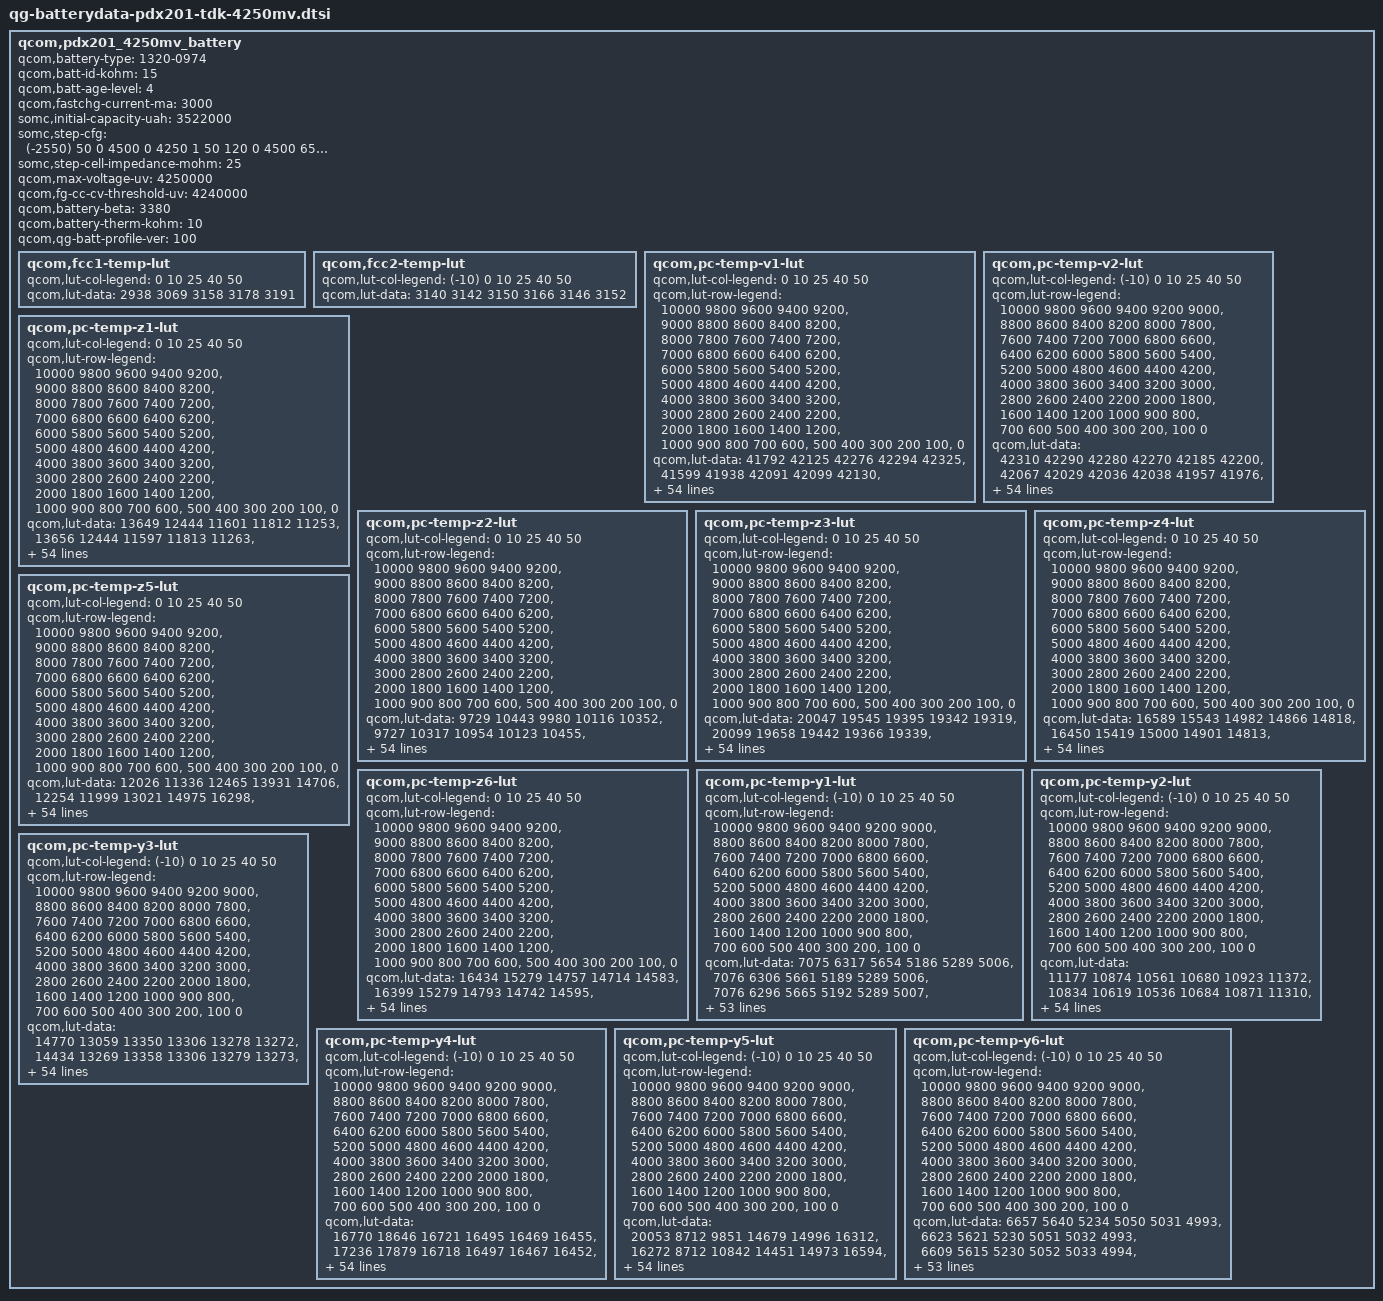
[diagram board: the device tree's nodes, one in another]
// SPDX-License-Identifier: GPL-2.0-only
/*
 * Copyright (c) 2019, The Linux Foundation. All rights reserved.
 */

qcom,pdx201_4250mv_battery {
	/* Added or Modified by SOMC */
	qcom,battery-type = "1320-0974";
	qcom,batt-id-kohm = <15>;
	qcom,batt-age-level = <4>;
	qcom,fastchg-current-ma = <3000>;
	somc,initial-capacity-uah = <3522000>;
	somc,step-cfg = <
		(-2550) 50    0 4500    0 4250 1
		   50  120    0 4500  650 4250 2
		  120  200    0 4100 1700 4250 3
		  120  200 4100 4200 1200 4250 3
		  120  200 4200 4500 1000 4250 3
		  200  450    0 4150 2400 4250 3
		  200  450 4150 4200 1700 4250 3
		  200  450 4200 4500 1350 4250 3
		  450  550    0 4500 1000 4200 4
		  550 2550    0 4500    0 4200 5
	>;
	somc,step-cell-impedance-mohm = <25>;

	/* Prepared by Qualcomm */
	/* 4176719_SoMC_Amuro2_3108mAh_averaged_MasterSlave_Sept16th2019 */
	qcom,max-voltage-uv = <4250000>;
	qcom,fg-cc-cv-threshold-uv = <4240000>;
	/* qcom,fastchg-current-ma = <1500>; */
	/* qcom,batt-id-kohm = <330>; */
	qcom,battery-beta = <3380>;
	qcom,battery-therm-kohm = <10>;
	/* qcom,battery-type = "4176719_SoMC_Amuro2_3108mAh_averaged_MasterSlave_Sept16th2019"; */
	qcom,qg-batt-profile-ver = <100>;

	qcom,fcc1-temp-lut {
		qcom,lut-col-legend = <0 10 25 40 50>;
		qcom,lut-data = <2938 3069 3158 3178 3191>;
	};

	qcom,fcc2-temp-lut {
		qcom,lut-col-legend = <(-10) 0 10 25 40 50>;
		qcom,lut-data = <3140 3142 3150 3166 3146 3152>;
	};

	qcom,pc-temp-v1-lut {
		qcom,lut-col-legend = <0 10 25 40 50>;
		qcom,lut-row-legend = <10000 9800 9600 9400 9200>,
			<9000 8800 8600 8400 8200>,
			<8000 7800 7600 7400 7200>,
			<7000 6800 6600 6400 6200>,
			<6000 5800 5600 5400 5200>,
			<5000 4800 4600 4400 4200>,
			<4000 3800 3600 3400 3200>,
			<3000 2800 2600 2400 2200>,
			<2000 1800 1600 1400 1200>,
			<1000 900 800 700 600>,
			<500 400 300 200 100>,
			<0>;
		qcom,lut-data = <41792 42125 42276 42294 42325>,
			<41599 41938 42091 42099 42130>,
			<41428 41750 41896 41903 41938>,
			<41291 41550 41695 41705 41739>,
			<41188 41357 41497 41509 41540>,
			<41059 41209 41298 41310 41344>,
			<40805 41099 41130 41123 41152>,
			<40462 40961 41006 40959 40964>,
			<40207 40692 40873 40802 40779>,
			<40026 40358 40639 40612 40599>,
			<39882 40132 40324 40382 40420>,
			<39774 39966 40111 40184 40250>,
			<39693 39837 39985 40042 40091>,
			<39611 39746 39876 39917 39940>,
			<39518 39670 39759 39783 39795>,
			<39422 39575 39642 39647 39656>,
			<39323 39457 39521 39511 39518>,
			<39218 39332 39397 39382 39389>,
			<39113 39213 39253 39242 39256>,
			<39012 39090 39043 39054 39086>,
			<38915 38942 38808 38829 38878>,
			<38822 38741 38665 38674 38713>,
			<38732 38570 38572 38578 38599>,
			<38647 38480 38495 38497 38503>,
			<38565 38417 38426 38414 38412>,
			<38484 38366 38365 38336 38330>,
			<38414 38323 38305 38264 38253>,
			<38358 38286 38244 38197 38183>,
			<38310 38251 38191 38137 38118>,
			<38275 38219 38145 38084 38060>,
			<38251 38189 38104 38038 38008>,
			<38230 38161 38071 37998 37963>,
			<38211 38134 38041 37964 37927>,
			<38193 38110 38012 37929 37888>,
			<38173 38088 37986 37893 37844>,
			<38145 38061 37955 37853 37796>,
			<38109 38024 37916 37805 37744>,
			<38062 37979 37867 37745 37688>,
			<37986 37913 37803 37675 37620>,
			<37889 37819 37714 37589 37533>,
			<37787 37713 37610 37488 37431>,
			<37672 37596 37494 37371 37313>,
			<37547 37469 37364 37239 37179>,
			<37417 37330 37222 37105 37044>,
			<37322 37229 37116 37005 36944>,
			<37268 37171 37060 36956 36894>,
			<37243 37152 37046 36941 36879>,
			<37222 37141 37031 36927 36867>,
			<37181 37110 37005 36892 36833>,
			<37020 36975 36874 36724 36653>,
			<36666 36637 36550 36391 36320>,
			<36217 36197 36116 35955 35881>,
			<35657 35636 35560 35400 35328>,
			<34913 34880 34817 34650 34579>,
			<33729 33724 33655 33512 33444>,
			<30000 30000 30000 30000 30000>;
	};

	qcom,pc-temp-v2-lut {
		qcom,lut-col-legend = <(-10) 0 10 25 40 50>;
		qcom,lut-row-legend = <10000 9800 9600 9400 9200 9000>,
			<8800 8600 8400 8200 8000 7800>,
			<7600 7400 7200 7000 6800 6600>,
			<6400 6200 6000 5800 5600 5400>,
			<5200 5000 4800 4600 4400 4200>,
			<4000 3800 3600 3400 3200 3000>,
			<2800 2600 2400 2200 2000 1800>,
			<1600 1400 1200 1000 900 800>,
			<700 600 500 400 300 200>,
			<100 0>;
		qcom,lut-data = <42310 42290 42280 42270 42185 42200>,
			<42067 42029 42036 42038 41957 41976>,
			<41837 41788 41808 41816 41738 41760>,
			<41614 41569 41594 41607 41531 41554>,
			<41391 41367 41392 41407 41335 41357>,
			<41221 41186 41207 41215 41143 41164>,
			<41129 41041 41048 41032 40957 40976>,
			<41044 40898 40893 40852 40774 40791>,
			<40817 40686 40703 40668 40589 40611>,
			<40320 40387 40475 40482 40405 40436>,
			<39934 40115 40245 40289 40232 40268>,
			<39745 39888 40002 40065 40073 40104>,
			<39601 39695 39783 39864 39924 39947>,
			<39471 39565 39654 39743 39781 39798>,
			<39360 39472 39567 39657 39645 39656>,
			<39227 39362 39457 39554 39508 39517>,
			<39047 39213 39289 39425 39371 39387>,
			<38837 39050 39107 39277 39226 39248>,
			<38586 38893 38945 39089 39044 39067>,
			<38294 38736 38791 38874 38832 38853>,
			<38139 38598 38656 38704 38664 38684>,
			<38086 38489 38539 38570 38541 38557>,
			<38049 38380 38433 38456 38437 38449>,
			<38007 38233 38339 38359 38344 38353>,
			<37968 38066 38256 38274 38261 38268>,
			<37929 37971 38180 38196 38184 38189>,
			<37891 37927 38112 38125 38113 38115>,
			<37855 37895 38045 38059 38048 38048>,
			<37818 37865 37969 38000 37990 37988>,
			<37782 37838 37893 37946 37935 37932>,
			<37746 37808 37842 37894 37885 37881>,
			<37711 37773 37809 37846 37840 37836>,
			<37674 37737 37777 37799 37791 37785>,
			<37636 37707 37742 37756 37724 37708>,
			<37596 37680 37705 37712 37645 37615>,
			<37553 37643 37666 37659 37567 37526>,
			<37505 37596 37625 37597 37490 37439>,
			<37451 37541 37577 37533 37417 37359>,
			<37384 37480 37517 37470 37355 37296>,
			<37307 37411 37445 37401 37295 37235>,
			<37233 37329 37362 37316 37217 37155>,
			<37160 37225 37261 37214 37117 37053>,
			<37090 37113 37142 37106 36999 36936>,
			<37024 36998 37014 36984 36876 36823>,
			<36964 36911 36923 36884 36819 36764>,
			<36877 36857 36884 36865 36797 36742>,
			<36826 36823 36868 36847 36778 36723>,
			<36765 36796 36841 36823 36749 36696>,
			<36681 36729 36798 36778 36680 36631>,
			<36512 36586 36659 36628 36474 36417>,
			<36223 36289 36330 36288 36100 36029>,
			<35819 35833 35849 35832 35623 35550>,
			<35238 35249 35255 35252 35017 34940>,
			<34434 34442 34481 34492 34196 34117>,
			<33138 33253 33383 33342 32988 32854>,
			<29569 29555 29575 29606 29655 29594>;
	};

	qcom,pc-temp-z1-lut {
		qcom,lut-col-legend = <0 10 25 40 50>;
		qcom,lut-row-legend = <10000 9800 9600 9400 9200>,
			<9000 8800 8600 8400 8200>,
			<8000 7800 7600 7400 7200>,
			<7000 6800 6600 6400 6200>,
			<6000 5800 5600 5400 5200>,
			<5000 4800 4600 4400 4200>,
			<4000 3800 3600 3400 3200>,
			<3000 2800 2600 2400 2200>,
			<2000 1800 1600 1400 1200>,
			<1000 900 800 700 600>,
			<500 400 300 200 100>,
			<0>;
		qcom,lut-data = <13649 12444 11601 11812 11253>,
			<13656 12444 11597 11813 11263>,
			<13663 12443 11597 11813 11265>,
			<13671 12444 11598 11814 11268>,
			<13680 12445 11599 11815 11271>,
			<13685 12445 11603 11819 11274>,
			<13685 12444 11604 11823 11277>,
			<13685 12443 11605 11829 11279>,
			<13683 12434 11605 11835 11280>,
			<13654 12418 11601 11835 11280>,
			<13624 12407 11591 11831 11280>,
			<13626 12398 11589 11829 11281>,
			<13646 12393 11592 11831 11282>,
			<13667 12400 11598 11835 11283>,
			<13684 12417 11602 11837 11284>,
			<13699 12436 11608 11837 11285>,
			<13701 12466 11611 11838 11285>,
			<13683 12485 11614 11839 11287>,
			<13663 12480 11617 11840 11288>,
			<13655 12470 11620 11842 11289>,
			<13651 12468 11625 11843 11290>,
			<13647 12476 11628 11844 11292>,
			<13643 12485 11631 11846 11293>,
			<13639 12490 11633 11847 11295>,
			<13639 12493 11637 11850 11297>,
			<13643 12496 11641 11852 11299>,
			<13649 12500 11645 11855 11300>,
			<13656 12505 11650 11858 11302>,
			<13665 12512 11653 11860 11303>,
			<13678 12521 11655 11863 11304>,
			<13715 12524 11657 11864 11305>,
			<13754 12515 11659 11865 11306>,
			<13755 12505 11661 11865 11308>,
			<13719 12515 11663 11865 11309>,
			<13686 12549 11666 11865 11309>,
			<13676 12568 11669 11866 11310>,
			<13668 12572 11672 11867 11311>,
			<13668 12574 11675 11870 11312>,
			<13713 12569 11677 11871 11313>,
			<13767 12553 11679 11870 11312>,
			<13767 12545 11681 11870 11312>,
			<13740 12565 11683 11870 11312>,
			<13734 12580 11685 11871 11312>,
			<13737 12557 11687 11871 11312>,
			<13615 12567 11691 11872 11313>,
			<13598 12546 11690 11872 11314>,
			<13590 12554 11690 11871 11313>,
			<13589 12567 11685 11871 11314>,
			<13597 12553 11688 11869 11316>,
			<13631 12551 11695 11871 11314>,
			<13694 12560 11700 11874 11316>,
			<13672 12586 11708 11880 11320>,
			<13657 12610 11726 11890 11327>,
			<13746 12663 11761 11907 11336>,
			<13746 12663 11761 11907 11336>,
			<13746 12663 11761 11907 11336>;
	};

	qcom,pc-temp-z2-lut {
		qcom,lut-col-legend = <0 10 25 40 50>;
		qcom,lut-row-legend = <10000 9800 9600 9400 9200>,
			<9000 8800 8600 8400 8200>,
			<8000 7800 7600 7400 7200>,
			<7000 6800 6600 6400 6200>,
			<6000 5800 5600 5400 5200>,
			<5000 4800 4600 4400 4200>,
			<4000 3800 3600 3400 3200>,
			<3000 2800 2600 2400 2200>,
			<2000 1800 1600 1400 1200>,
			<1000 900 800 700 600>,
			<500 400 300 200 100>,
			<0>;
		qcom,lut-data = <9729 10443 9980 10116 10352>,
			<9727 10317 10954 10123 10455>,
			<9727 10181 10805 10635 10537>,
			<9728 9993 10624 11384 10969>,
			<9737 9829 10582 11547 11150>,
			<9748 9804 10567 11388 11083>,
			<9761 9808 10540 11250 11017>,
			<9776 9810 10464 11205 11024>,
			<9783 9806 10401 11179 11054>,
			<9785 9798 10421 11180 11079>,
			<9787 9799 10478 11199 11106>,
			<9788 9816 10476 11203 11122>,
			<9789 9837 10255 10794 10903>,
			<9790 9860 10067 10263 10516>,
			<9789 9885 10094 10204 10439>,
			<9787 9910 10157 10223 10459>,
			<9786 9936 10174 10235 10471>,
			<9788 9958 10174 10242 10471>,
			<9791 9971 10174 10248 10471>,
			<9797 9980 10173 10268 10472>,
			<9809 9994 10170 10302 10472>,
			<9819 10020 10166 10308 10475>,
			<9827 10037 10159 10280 10533>,
			<9835 10036 10156 10268 10594>,
			<9842 10030 10174 10305 10565>,
			<9850 10024 10204 10361 10472>,
			<9856 10019 10221 10390 10409>,
			<9860 10015 10234 10391 10369>,
			<9862 10016 10238 10384 10347>,
			<9865 10019 10226 10374 10351>,
			<9868 10023 10212 10362 10362>,
			<9871 10027 10212 10367 10381>,
			<9873 10031 10218 10384 10427>,
			<9874 10036 10226 10403 10476>,
			<9876 10042 10237 10427 10520>,
			<9878 10048 10250 10456 10560>,
			<9882 10053 10261 10484 10585>,
			<9886 10059 10272 10515 10603>,
			<9893 10067 10284 10535 10620>,
			<9902 10076 10304 10552 10637>,
			<9912 10082 10318 10563 10652>,
			<9927 10084 10312 10548 10664>,
			<9949 10087 10303 10518 10673>,
			<9995 10107 10307 10535 10664>,
			<10236 10225 10350 10569 10674>,
			<10237 10276 10417 10558 10697>,
			<10239 10269 10401 10548 10667>,
			<10234 10267 10400 10546 10716>,
			<10248 10300 10408 10588 10909>,
			<10275 10325 10479 10671 10606>,
			<10265 10286 10445 10562 10594>,
			<10164 10223 10403 10469 10424>,
			<10054 10194 10323 10412 10449>,
			<9661 10145 10382 10360 10415>,
			<9661 10145 10382 10360 10415>,
			<9661 10145 10382 10360 10415>;
	};

	qcom,pc-temp-z3-lut {
		qcom,lut-col-legend = <0 10 25 40 50>;
		qcom,lut-row-legend = <10000 9800 9600 9400 9200>,
			<9000 8800 8600 8400 8200>,
			<8000 7800 7600 7400 7200>,
			<7000 6800 6600 6400 6200>,
			<6000 5800 5600 5400 5200>,
			<5000 4800 4600 4400 4200>,
			<4000 3800 3600 3400 3200>,
			<3000 2800 2600 2400 2200>,
			<2000 1800 1600 1400 1200>,
			<1000 900 800 700 600>,
			<500 400 300 200 100>,
			<0>;
		qcom,lut-data = <20047 19545 19395 19342 19319>,
			<20099 19658 19442 19366 19339>,
			<20127 19732 19473 19395 19347>,
			<20125 19777 19515 19416 19361>,
			<20098 19805 19544 19431 19369>,
			<20072 19802 19570 19442 19371>,
			<20059 19770 19578 19449 19372>,
			<20048 19749 19572 19447 19370>,
			<20033 19764 19563 19441 19368>,
			<20008 19786 19557 19438 19366>,
			<19981 19787 19549 19437 19365>,
			<19957 19759 19532 19435 19364>,
			<19933 19726 19466 19406 19351>,
			<19922 19694 19414 19368 19331>,
			<19926 19665 19415 19361 19327>,
			<19936 19659 19422 19359 19327>,
			<19947 19662 19431 19359 19327>,
			<19960 19666 19446 19362 19327>,
			<19975 19673 19465 19367 19328>,
			<19991 19683 19490 19372 19328>,
			<20008 19699 19513 19379 19325>,
			<20020 19734 19515 19380 19324>,
			<20025 19760 19501 19367 19328>,
			<20029 19756 19487 19356 19336>,
			<20034 19743 19475 19361 19346>,
			<20041 19731 19467 19375 19358>,
			<20046 19719 19471 19385 19363>,
			<20043 19708 19494 19405 19365>,
			<20034 19702 19509 19417 19366>,
			<20022 19696 19512 19415 19365>,
			<20003 19694 19513 19412 19363>,
			<19981 19692 19512 19407 19360>,
			<19967 19691 19506 19401 19355>,
			<19957 19691 19500 19395 19352>,
			<19950 19691 19495 19389 19350>,
			<19945 19691 19490 19385 19349>,
			<19941 19687 19488 19382 19347>,
			<19936 19680 19487 19381 19346>,
			<19929 19675 19485 19380 19344>,
			<19920 19671 19481 19379 19341>,
			<19907 19667 19476 19379 19340>,
			<19885 19659 19469 19373 19340>,
			<19856 19649 19461 19364 19342>,
			<19809 19633 19459 19366 19343>,
			<19668 19577 19446 19365 19339>,
			<19646 19545 19426 19349 19326>,
			<19643 19541 19415 19341 19326>,
			<19634 19527 19413 19342 19317>,
			<19616 19519 19412 19335 19308>,
			<19608 19516 19394 19332 19341>,
			<19608 19521 19399 19339 19325>,
			<19618 19519 19399 19347 19350>,
			<19566 19495 19389 19352 19335>,
			<19416 19464 19358 19357 19335>,
			<19416 19464 19358 19357 19335>,
			<19416 19464 19358 19357 19335>;
	};

	qcom,pc-temp-z4-lut {
		qcom,lut-col-legend = <0 10 25 40 50>;
		qcom,lut-row-legend = <10000 9800 9600 9400 9200>,
			<9000 8800 8600 8400 8200>,
			<8000 7800 7600 7400 7200>,
			<7000 6800 6600 6400 6200>,
			<6000 5800 5600 5400 5200>,
			<5000 4800 4600 4400 4200>,
			<4000 3800 3600 3400 3200>,
			<3000 2800 2600 2400 2200>,
			<2000 1800 1600 1400 1200>,
			<1000 900 800 700 600>,
			<500 400 300 200 100>,
			<0>;
		qcom,lut-data = <16589 15543 14982 14866 14818>,
			<16450 15419 15000 14901 14813>,
			<16316 15324 14956 14890 14835>,
			<16186 15257 14890 14830 14800>,
			<16054 15203 14843 14786 14769>,
			<15949 15145 14802 14755 14744>,
			<15889 15086 14764 14730 14724>,
			<15843 15038 14720 14712 14714>,
			<15783 15007 14692 14697 14707>,
			<15692 14982 14694 14688 14699>,
			<15598 14953 14705 14680 14689>,
			<15525 14917 14724 14678 14681>,
			<15464 14892 14770 14694 14686>,
			<15407 14884 14805 14715 14696>,
			<15350 14878 14797 14714 14694>,
			<15296 14871 14777 14703 14683>,
			<15251 14861 14757 14697 14677>,
			<15213 14854 14734 14694 14678>,
			<15179 14851 14722 14693 14678>,
			<15144 14850 14770 14731 14704>,
			<15109 14856 14854 14830 14795>,
			<15088 14914 14880 14867 14835>,
			<15077 14967 14887 14870 14828>,
			<15070 14974 14890 14871 14814>,
			<15069 14977 14885 14860 14793>,
			<15075 14977 14875 14829 14764>,
			<15079 14971 14858 14800 14741>,
			<15079 14961 14822 14764 14725>,
			<15076 14950 14794 14737 14712>,
			<15072 14938 14779 14724 14702>,
			<15065 14926 14768 14715 14693>,
			<15057 14915 14764 14709 14687>,
			<15049 14905 14761 14704 14682>,
			<15042 14897 14760 14703 14679>,
			<15035 14890 14762 14708 14688>,
			<15026 14888 14766 14717 14703>,
			<15017 14892 14771 14728 14709>,
			<15013 14898 14779 14742 14713>,
			<15012 14903 14785 14747 14714>,
			<15011 14908 14789 14746 14714>,
			<15009 14910 14792 14745 14713>,
			<15002 14906 14795 14750 14712>,
			<14988 14899 14797 14760 14710>,
			<14954 14878 14790 14757 14710>,
			<14853 14811 14761 14740 14707>,
			<14838 14773 14720 14705 14682>,
			<14827 14770 14718 14695 14664>,
			<14823 14765 14708 14676 14657>,
			<14818 14757 14703 14682 14662>,
			<14821 14764 14733 14713 14653>,
			<14843 14773 14739 14712 14673>,
			<14842 14779 14736 14704 14650>,
			<14906 14793 14742 14696 14664>,
			<15074 14815 14771 14688 14662>,
			<15074 14815 14771 14688 14662>,
			<15074 14815 14771 14688 14662>;
	};

	qcom,pc-temp-z5-lut {
		qcom,lut-col-legend = <0 10 25 40 50>;
		qcom,lut-row-legend = <10000 9800 9600 9400 9200>,
			<9000 8800 8600 8400 8200>,
			<8000 7800 7600 7400 7200>,
			<7000 6800 6600 6400 6200>,
			<6000 5800 5600 5400 5200>,
			<5000 4800 4600 4400 4200>,
			<4000 3800 3600 3400 3200>,
			<3000 2800 2600 2400 2200>,
			<2000 1800 1600 1400 1200>,
			<1000 900 800 700 600>,
			<500 400 300 200 100>,
			<0>;
		qcom,lut-data = <12026 11336 12465 13931 14706>,
			<12254 11999 13021 14975 16298>,
			<12404 12701 13746 15806 15722>,
			<12426 13643 15048 16813 16358>,
			<12427 14461 16522 18050 17120>,
			<12430 14558 18441 19849 18118>,
			<12522 14415 20471 21343 19148>,
			<12718 14323 23080 22214 19871>,
			<12861 15104 24888 23092 20476>,
			<12952 16401 24594 24008 21292>,
			<13025 16843 23309 25154 22670>,
			<13077 16990 21380 25602 23537>,
			<13111 17049 17077 22172 21455>,
			<13168 16712 13934 17829 17758>,
			<13413 16116 14133 17402 17120>,
			<13879 16082 14908 17876 17963>,
			<14403 17063 15967 18436 18906>,
			<15035 18392 17767 19947 19834>,
			<15814 19507 20446 21754 20571>,
			<16822 20800 27056 23000 20192>,
			<18131 23251 35164 24338 18357>,
			<19417 29920 35384 24094 16800>,
			<20563 35087 27750 19999 15649>,
			<21673 33502 21385 16256 14929>,
			<22826 28975 18758 15700 15180>,
			<24216 25716 17117 15914 16127>,
			<25105 23512 17281 16727 17152>,
			<25141 22065 18999 18644 18271>,
			<25120 21571 20829 20671 19560>,
			<25070 21276 22577 22329 21114>,
			<24336 21213 24055 23841 22854>,
			<23254 21544 24706 25071 24451>,
			<22662 22068 25122 26200 26128>,
			<22254 22628 25235 26639 26923>,
			<22046 23286 24984 25932 26356>,
			<22160 23536 24552 24659 25152>,
			<22512 23392 24066 23379 23674>,
			<22964 23147 23436 21868 21600>,
			<23827 22915 22746 20744 20119>,
			<24630 22657 21986 20063 19288>,
			<24592 22382 21147 19404 18717>,
			<24019 22012 20002 18152 18404>,
			<23873 21820 19054 16754 18188>,
			<23894 22071 19297 16725 17932>,
			<25277 23841 20274 17291 17449>,
			<23855 24086 21448 17641 17419>,
			<24039 23899 19937 17193 19155>,
			<23147 22264 20437 18568 18369>,
			<22085 22544 21091 17734 16739>,
			<21824 22012 17413 14959 20369>,
			<20007 20317 16699 14947 15936>,
			<19100 18783 16398 15393 21335>,
			<15096 16267 15516 15692 17010>,
			<11712 14307 13324 16355 16915>,
			<11712 14307 13324 16355 16915>,
			<11712 14307 13324 16355 16915>;
	};

	qcom,pc-temp-z6-lut {
		qcom,lut-col-legend = <0 10 25 40 50>;
		qcom,lut-row-legend = <10000 9800 9600 9400 9200>,
			<9000 8800 8600 8400 8200>,
			<8000 7800 7600 7400 7200>,
			<7000 6800 6600 6400 6200>,
			<6000 5800 5600 5400 5200>,
			<5000 4800 4600 4400 4200>,
			<4000 3800 3600 3400 3200>,
			<3000 2800 2600 2400 2200>,
			<2000 1800 1600 1400 1200>,
			<1000 900 800 700 600>,
			<500 400 300 200 100>,
			<0>;
		qcom,lut-data = <16434 15279 14757 14714 14583>,
			<16399 15279 14793 14742 14595>,
			<16355 15279 14789 14748 14607>,
			<16302 15272 14783 14740 14601>,
			<16234 15257 14778 14732 14594>,
			<16173 15233 14773 14725 14586>,
			<16134 15189 14765 14718 14578>,
			<16101 15156 14743 14710 14572>,
			<16061 15147 14724 14701 14567>,
			<16003 15141 14721 14695 14563>,
			<15945 15126 14720 14692 14558>,
			<15903 15095 14717 14687 14554>,
			<15868 15066 14703 14677 14548>,
			<15843 15048 14689 14665 14542>,
			<15826 15035 14683 14658 14537>,
			<15814 15032 14680 14653 14532>,
			<15804 15031 14679 14651 14530>,
			<15797 15031 14680 14652 14530>,
			<15791 15033 14682 14653 14531>,
			<15784 15040 14714 14673 14542>,
			<15777 15053 14765 14720 14580>,
			<15772 15098 14775 14735 14597>,
			<15770 15134 14772 14731 14597>,
			<15768 15134 14767 14726 14596>,
			<15769 15129 14760 14722 14593>,
			<15779 15124 14752 14717 14586>,
			<15788 15116 14747 14712 14580>,
			<15785 15108 14744 14707 14574>,
			<15777 15101 14740 14702 14569>,
			<15767 15094 14736 14696 14563>,
			<15753 15088 14732 14690 14558>,
			<15738 15082 14728 14684 14553>,
			<15729 15077 14724 14678 14548>,
			<15723 15077 14722 14675 14545>,
			<15719 15078 14721 14675 14549>,
			<15716 15078 14720 14675 14553>,
			<15715 15078 14721 14677 14555>,
			<15712 15077 14725 14683 14555>,
			<15707 15077 14726 14685 14555>,
			<15700 15079 14726 14684 14554>,
			<15690 15079 14725 14683 14553>,
			<15676 15076 14724 14682 14553>,
			<15654 15068 14721 14682 14553>,
			<15611 15052 14716 14681 14553>,
			<15497 14997 14698 14674 14550>,
			<15477 14964 14670 14650 14532>,
			<15470 14959 14663 14642 14525>,
			<15463 14950 14657 14633 14515>,
			<15459 14942 14654 14632 14514>,
			<15465 14949 14659 14644 14527>,
			<15482 14959 14665 14649 14528>,
			<15497 14970 14666 14651 14532>,
			<15519 14975 14668 14652 14532>,
			<15553 14992 14672 14654 14533>,
			<15553 14992 14672 14654 14533>,
			<15553 14992 14672 14654 14533>;
	};

	qcom,pc-temp-y1-lut {
		qcom,lut-col-legend = <(-10) 0 10 25 40 50>;
		qcom,lut-row-legend = <10000 9800 9600 9400 9200 9000>,
			<8800 8600 8400 8200 8000 7800>,
			<7600 7400 7200 7000 6800 6600>,
			<6400 6200 6000 5800 5600 5400>,
			<5200 5000 4800 4600 4400 4200>,
			<4000 3800 3600 3400 3200 3000>,
			<2800 2600 2400 2200 2000 1800>,
			<1600 1400 1200 1000 900 800>,
			<700 600 500 400 300 200>,
			<100 0>;
		qcom,lut-data = <7075 6317 5654 5186 5289 5006>,
			<7076 6306 5661 5189 5289 5006>,
			<7076 6296 5665 5192 5289 5007>,
			<7075 6286 5667 5193 5289 5008>,
			<7074 6276 5667 5194 5289 5008>,
			<7072 6267 5667 5194 5289 5009>,
			<7069 6256 5664 5193 5289 5009>,
			<7067 6248 5659 5192 5290 5009>,
			<7072 6248 5659 5192 5290 5009>,
			<7099 6256 5659 5193 5288 5010>,
			<7119 6264 5659 5195 5288 5011>,
			<7128 6274 5673 5197 5290 5011>,
			<7134 6283 5688 5199 5292 5011>,
			<7126 6283 5687 5199 5292 5012>,
			<7097 6280 5678 5200 5291 5014>,
			<7084 6277 5674 5200 5291 5014>,
			<7102 6276 5674 5201 5292 5013>,
			<7124 6275 5675 5203 5293 5013>,
			<7119 6282 5677 5205 5294 5013>,
			<7099 6304 5682 5208 5295 5015>,
			<7092 6312 5684 5211 5296 5016>,
			<7107 6301 5682 5212 5298 5017>,
			<7122 6290 5680 5214 5299 5018>,
			<7113 6290 5682 5216 5301 5019>,
			<7086 6295 5689 5219 5302 5020>,
			<7077 6299 5694 5222 5303 5021>,
			<7091 6302 5695 5226 5303 5022>,
			<7111 6305 5698 5230 5304 5023>,
			<7131 6318 5703 5233 5305 5024>,
			<7150 6339 5711 5237 5306 5026>,
			<7154 6344 5719 5241 5307 5027>,
			<7130 6326 5726 5246 5309 5027>,
			<7107 6311 5732 5250 5311 5028>,
			<7104 6311 5738 5255 5312 5029>,
			<7102 6312 5743 5259 5314 5030>,
			<7097 6315 5748 5261 5315 5031>,
			<7075 6320 5753 5263 5317 5033>,
			<7057 6328 5756 5265 5318 5033>,
			<7053 6348 5753 5267 5317 5033>,
			<7050 6375 5749 5269 5317 5033>,
			<7067 6374 5749 5270 5317 5033>,
			<7163 6336 5751 5271 5317 5033>,
			<7173 6327 5760 5274 5318 5034>,
			<7092 6329 5771 5277 5318 5035>,
			<7049 6310 5761 5274 5318 5035>,
			<7063 6343 5761 5279 5317 5033>,
			<7065 6316 5762 5276 5320 5033>,
			<7066 6319 5760 5283 5319 5032>,
			<7072 6370 5768 5280 5319 5032>,
			<7078 6344 5777 5281 5319 5034>,
			<7090 6331 5776 5290 5324 5034>,
			<7133 6346 5793 5305 5330 5037>,
			<7186 6367 5818 5317 5336 5042>,
			<7245 6412 5833 5330 5343 5045>,
			<7245 6412 5833 5330 5343 5045>,
			<7245 6412 5833 5330 5343 5045>;
	};

	qcom,pc-temp-y2-lut {
		qcom,lut-col-legend = <(-10) 0 10 25 40 50>;
		qcom,lut-row-legend = <10000 9800 9600 9400 9200 9000>,
			<8800 8600 8400 8200 8000 7800>,
			<7600 7400 7200 7000 6800 6600>,
			<6400 6200 6000 5800 5600 5400>,
			<5200 5000 4800 4600 4400 4200>,
			<4000 3800 3600 3400 3200 3000>,
			<2800 2600 2400 2200 2000 1800>,
			<1600 1400 1200 1000 900 800>,
			<700 600 500 400 300 200>,
			<100 0>;
		qcom,lut-data = <11177 10874 10561 10680 10923 11372>,
			<10834 10619 10536 10684 10871 11310>,
			<10560 10454 10511 10686 10830 11240>,
			<10360 10360 10488 10686 10801 11172>,
			<10238 10318 10468 10684 10783 11116>,
			<10200 10309 10453 10682 10778 11081>,
			<10270 10375 10441 10666 10791 11064>,
			<10391 10475 10432 10648 10810 11052>,
			<10477 10516 10436 10654 10813 11040>,
			<10549 10537 10459 10687 10807 11028>,
			<10608 10549 10488 10714 10803 11024>,
			<10663 10554 10527 10735 10803 11061>,
			<10701 10559 10568 10748 10808 11103>,
			<10662 10577 10593 10748 10824 11086>,
			<10478 10619 10611 10746 10852 11020>,
			<10265 10657 10630 10747 10878 10997>,
			<9990 10685 10653 10773 10945 11085>,
			<9758 10709 10677 10807 11010 11176>,
			<9701 10739 10706 10827 11017 11171>,
			<9676 10771 10739 10845 11004 11144>,
			<9665 10779 10771 10870 11002 11136>,
			<9660 10734 10801 10908 11021 11157>,
			<9656 10688 10830 10948 11044 11184>,
			<9655 10697 10866 10978 11058 11199>,
			<9654 10726 10902 11007 11079 11211>,
			<9653 10732 10909 11042 11108 11228>,
			<9653 10673 10886 11087 11155 11251>,
			<9653 10609 10867 11128 11204 11281>,
			<9653 10592 10885 11166 11240 11327>,
			<9653 10584 10921 11196 11276 11386>,
			<9653 10530 10923 11193 11326 11439>,
			<9653 10142 10865 11165 11412 11488>,
			<9653 9789 10795 11145 11475 11531>,
			<9653 9722 10736 11139 11464 11562>,
			<9653 9686 10678 11135 11417 11590>,
			<9653 9676 10633 11126 11399 11631>,
			<9653 9674 10598 11112 11396 11693>,
			<9653 9672 10568 11093 11399 11724>,
			<9653 9669 10541 11057 11430 11692>,
			<9653 9666 10517 11027 11478 11641>,
			<9653 9664 10492 11025 11466 11615>,
			<9653 9661 10466 11025 11380 11599>,
			<9652 9659 10438 11007 11327 11602>,
			<9652 9657 10410 10962 11294 11604>,
			<9652 9657 10393 10961 11303 11467>,
			<9652 9657 10415 10958 11323 11438>,
			<9652 9657 10391 10935 11315 11389>,
			<9652 9656 10371 10947 11235 11297>,
			<9652 9655 10360 10938 11214 11232>,
			<9652 9655 10349 10918 11185 11233>,
			<9652 9654 10325 10873 11111 11213>,
			<9651 9653 10271 10778 11082 11083>,
			<9650 9652 10225 10749 10972 10993>,
			<9649 9651 10192 10716 10870 10893>,
			<9649 9651 10192 10716 10870 10893>,
			<9649 9651 10192 10716 10870 10893>;
	};

	qcom,pc-temp-y3-lut {
		qcom,lut-col-legend = <(-10) 0 10 25 40 50>;
		qcom,lut-row-legend = <10000 9800 9600 9400 9200 9000>,
			<8800 8600 8400 8200 8000 7800>,
			<7600 7400 7200 7000 6800 6600>,
			<6400 6200 6000 5800 5600 5400>,
			<5200 5000 4800 4600 4400 4200>,
			<4000 3800 3600 3400 3200 3000>,
			<2800 2600 2400 2200 2000 1800>,
			<1600 1400 1200 1000 900 800>,
			<700 600 500 400 300 200>,
			<100 0>;
		qcom,lut-data = <14770 13059 13350 13306 13278 13272>,
			<14434 13269 13358 13306 13279 13273>,
			<14085 13428 13366 13306 13280 13274>,
			<13775 13540 13374 13306 13281 13276>,
			<13556 13605 13381 13307 13282 13276>,
			<13478 13624 13385 13307 13283 13277>,
			<13553 13568 13387 13308 13283 13277>,
			<13656 13491 13388 13308 13283 13277>,
			<13669 13478 13392 13308 13283 13277>,
			<13657 13476 13399 13306 13286 13278>,
			<13639 13475 13402 13305 13287 13278>,
			<13589 13471 13394 13310 13288 13277>,
			<13528 13468 13385 13315 13288 13276>,
			<13495 13466 13388 13319 13288 13277>,
			<13471 13465 13400 13322 13288 13279>,
			<13464 13463 13404 13324 13289 13281>,
			<13488 13456 13396 13325 13291 13284>,
			<13515 13445 13385 13326 13294 13286>,
			<13510 13433 13376 13323 13292 13283>,
			<13486 13419 13367 13315 13285 13277>,
			<13480 13405 13359 13310 13281 13275>,
			<13573 13385 13353 13307 13280 13275>,
			<13718 13372 13348 13304 13280 13275>,
			<13850 13371 13347 13301 13280 13275>,
			<13990 13371 13346 13299 13280 13276>,
			<14112 13372 13344 13298 13280 13276>,
			<14216 13380 13339 13298 13280 13276>,
			<14304 13390 13336 13299 13281 13276>,
			<14375 13398 13336 13300 13282 13276>,
			<14434 13406 13336 13301 13284 13277>,
			<14487 13407 13337 13301 13285 13277>,
			<14536 13402 13342 13300 13285 13277>,
			<14581 13395 13348 13299 13286 13277>,
			<14627 13388 13354 13300 13284 13275>,
			<14672 13383 13361 13300 13281 13272>,
			<14717 13385 13367 13301 13279 13272>,
			<14760 13420 13374 13303 13278 13272>,
			<14804 13463 13380 13303 13277 13272>,
			<14848 13495 13383 13303 13278 13272>,
			<14893 13527 13386 13303 13280 13274>,
			<14942 13562 13388 13303 13281 13274>,
			<14996 13601 13390 13304 13281 13273>,
			<15068 13655 13391 13305 13281 13273>,
			<15158 13731 13392 13307 13280 13274>,
			<15225 13819 13393 13302 13281 13274>,
			<15017 13758 13386 13307 13283 13275>,
			<15153 13805 13395 13306 13285 13276>,
			<15295 13909 13399 13307 13286 13282>,
			<15460 13983 13414 13312 13289 13286>,
			<15595 14103 13419 13312 13289 13283>,
			<15775 14229 13422 13312 13289 13281>,
			<16291 14442 13426 13321 13292 13284>,
			<16868 14795 13448 13329 13297 13287>,
			<17634 15269 13485 13339 13299 13289>,
			<17634 15269 13485 13339 13299 13289>,
			<17634 15269 13485 13339 13299 13289>;
	};

	qcom,pc-temp-y4-lut {
		qcom,lut-col-legend = <(-10) 0 10 25 40 50>;
		qcom,lut-row-legend = <10000 9800 9600 9400 9200 9000>,
			<8800 8600 8400 8200 8000 7800>,
			<7600 7400 7200 7000 6800 6600>,
			<6400 6200 6000 5800 5600 5400>,
			<5200 5000 4800 4600 4400 4200>,
			<4000 3800 3600 3400 3200 3000>,
			<2800 2600 2400 2200 2000 1800>,
			<1600 1400 1200 1000 900 800>,
			<700 600 500 400 300 200>,
			<100 0>;
		qcom,lut-data = <16770 18646 16721 16495 16469 16455>,
			<17236 17879 16718 16497 16467 16452>,
			<17920 17407 16716 16501 16466 16450>,
			<18634 17158 16716 16506 16468 16450>,
			<19190 17062 16718 16511 16471 16452>,
			<19400 17047 16720 16518 16475 16454>,
			<19363 17273 16745 16526 16481 16457>,
			<19271 17582 16777 16535 16488 16461>,
			<19010 17579 16781 16543 16491 16466>,
			<18349 17386 16779 16550 16495 16470>,
			<18017 17270 16778 16556 16499 16476>,
			<18099 17249 16789 16560 16511 16484>,
			<18202 17239 16809 16564 16527 16492>,
			<18213 17267 16842 16575 16539 16500>,
			<18209 17367 16895 16596 16548 16507>,
			<18198 17413 16914 16620 16559 16517>,
			<18016 17368 16868 16654 16579 16537>,
			<17724 17297 16804 16676 16595 16553>,
			<17440 17239 16763 16647 16577 16540>,
			<17128 17182 16729 16575 16520 16500>,
			<17019 17138 16714 16538 16490 16477>,
			<17034 17112 16707 16521 16481 16465>,
			<17054 17082 16703 16513 16477 16460>,
			<17066 16962 16705 16517 16478 16460>,
			<17076 16739 16710 16525 16482 16461>,
			<17087 16664 16715 16532 16487 16462>,
			<17099 16691 16720 16538 16494 16467>,
			<17111 16733 16724 16544 16503 16473>,
			<17124 16773 16689 16553 16512 16481>,
			<17137 16819 16622 16562 16522 16491>,
			<17150 16874 16608 16567 16534 16502>,
			<17163 16946 16631 16570 16549 16515>,
			<17175 17017 16661 16571 16558 16523>,
			<17185 17083 16687 16571 16546 16510>,
			<17193 17140 16714 16570 16519 16486>,
			<17194 17151 16733 16565 16505 16477>,
			<17189 17136 16748 16555 16498 16472>,
			<17182 17124 16762 16550 16495 16470>,
			<17172 17125 16775 16553 16500 16473>,
			<17163 17128 16788 16557 16508 16477>,
			<17162 17131 16798 16558 16509 16477>,
			<17177 17134 16808 16558 16508 16476>,
			<17204 17135 16819 16568 16505 16475>,
			<17254 17129 16827 16573 16499 16475>,
			<17292 17092 16804 16542 16499 16473>,
			<17242 17094 16769 16551 16512 16484>,
			<17284 17133 16798 16567 16518 16489>,
			<17319 17196 16832 16585 16526 16495>,
			<17348 17265 16883 16603 16532 16503>,
			<17342 17275 16903 16585 16511 16483>,
			<17332 17256 16879 16583 16503 16473>,
			<17510 17246 16895 16606 16509 16485>,
			<17797 17277 16955 16645 16537 16512>,
			<18407 17490 17047 16733 16602 16578>,
			<18407 17490 17047 16733 16602 16578>,
			<18407 17490 17047 16733 16602 16578>;
	};

	qcom,pc-temp-y5-lut {
		qcom,lut-col-legend = <(-10) 0 10 25 40 50>;
		qcom,lut-row-legend = <10000 9800 9600 9400 9200 9000>,
			<8800 8600 8400 8200 8000 7800>,
			<7600 7400 7200 7000 6800 6600>,
			<6400 6200 6000 5800 5600 5400>,
			<5200 5000 4800 4600 4400 4200>,
			<4000 3800 3600 3400 3200 3000>,
			<2800 2600 2400 2200 2000 1800>,
			<1600 1400 1200 1000 900 800>,
			<700 600 500 400 300 200>,
			<100 0>;
		qcom,lut-data = <20053 8712 9851 14679 14996 16312>,
			<16272 8712 10842 14451 14973 16594>,
			<13604 10092 11540 14215 14871 16678>,
			<11895 12314 11985 13969 14704 16608>,
			<10993 13588 12218 13715 14483 16430>,
			<10748 13965 12279 13453 14221 16187>,
			<11796 12805 11996 13164 13843 15811>,
			<13243 11214 11620 12886 13465 15344>,
			<13423 11198 11820 12648 13351 14928>,
			<13286 12053 12769 12427 13527 14531>,
			<13164 12498 13237 12364 13650 14116>,
			<13079 12367 13052 12717 13462 13559>,
			<13022 12205 12834 13173 13205 13131>,
			<13198 12269 13052 13354 13104 13148>,
			<13978 12601 13863 13461 12924 13360>,
			<14889 12935 14404 13625 12909 13630>,
			<16140 13228 14663 13916 13442 14031>,
			<17150 13495 14806 14282 14116 14467>,
			<16067 13675 14699 14782 14467 14769>,
			<12519 13807 14353 15338 14727 15019>,
			<11022 14045 14077 15451 14772 15430>,
			<11049 14811 13857 15173 14690 16402>,
			<11092 15486 13727 14781 14580 17144>,
			<11135 15400 13808 14262 14438 17066>,
			<11185 14979 14078 13718 14208 16759>,
			<11230 14499 14436 13621 14054 16370>,
			<11270 13840 15030 13711 14026 15720>,
			<11306 13319 15668 13861 14135 15293>,
			<11340 13195 16265 14210 14466 15332>,
			<11372 13135 16795 14776 14982 15438>,
			<11403 12952 16856 15486 15397 15536>,
			<11433 12182 16425 16475 15768 15642>,
			<11466 11490 15877 16925 16081 15699>,
			<11513 11308 15310 16925 16356 15595>,
			<11574 11201 14766 16926 16560 15418>,
			<11657 11195 14586 16917 16387 15368>,
			<11798 11322 14539 16873 15553 15358>,
			<11890 11468 14472 16776 14978 15347>,
			<11813 11577 14218 16134 14974 15327>,
			<11630 11667 13832 15418 15044 15295>,
			<11463 11661 13517 15232 15013 15137>,
			<11299 11512 13236 15135 15015 14745>,
			<11236 11366 12925 14903 15035 14781>,
			<11220 11260 12721 14943 14976 14983>,
			<11431 11395 12846 14717 14694 15064>,
			<11425 11386 13085 15692 14240 14028>,
			<11458 11254 13114 14799 14309 13786>,
			<11651 11413 12895 14143 14051 15189>,
			<12075 11365 13082 14251 14339 16754>,
			<12162 11609 13150 14640 15126 16585>,
			<11839 11595 13410 14681 15964 16329>,
			<11312 11420 13024 15867 16809 17995>,
			<10651 11489 13024 16491 17826 19253>,
			<10299 10978 13759 16795 17346 18473>,
			<10299 10978 13759 16795 17346 18473>,
			<10299 10978 13759 16795 17346 18473>;
	};

	qcom,pc-temp-y6-lut {
		qcom,lut-col-legend = <(-10) 0 10 25 40 50>;
		qcom,lut-row-legend = <10000 9800 9600 9400 9200 9000>,
			<8800 8600 8400 8200 8000 7800>,
			<7600 7400 7200 7000 6800 6600>,
			<6400 6200 6000 5800 5600 5400>,
			<5200 5000 4800 4600 4400 4200>,
			<4000 3800 3600 3400 3200 3000>,
			<2800 2600 2400 2200 2000 1800>,
			<1600 1400 1200 1000 900 800>,
			<700 600 500 400 300 200>,
			<100 0>;
		qcom,lut-data = <6657 5640 5234 5050 5031 4993>,
			<6623 5621 5230 5051 5032 4993>,
			<6609 5615 5230 5052 5033 4994>,
			<6609 5619 5232 5054 5035 4995>,
			<6619 5630 5235 5056 5036 4996>,
			<6635 5645 5241 5058 5038 4997>,
			<6679 5674 5249 5061 5040 4999>,
			<6727 5704 5258 5064 5041 5000>,
			<6688 5695 5263 5066 5043 5002>,
			<6504 5641 5266 5067 5045 5003>,
			<6406 5607 5267 5068 5048 5005>,
			<6411 5602 5266 5072 5052 5007>,
			<6420 5598 5266 5077 5057 5009>,
			<6429 5607 5273 5083 5060 5011>,
			<6439 5639 5297 5091 5063 5015>,
			<6443 5653 5307 5100 5066 5019>,
			<6418 5636 5288 5110 5074 5027>,
			<6375 5610 5262 5117 5080 5033>,
			<6323 5588 5245 5106 5073 5027>,
			<6259 5567 5230 5080 5051 5011>,
			<6241 5548 5221 5065 5040 5002>,
			<6372 5535 5215 5058 5037 4999>,
			<6559 5521 5211 5054 5035 4997>,
			<6691 5488 5212 5054 5035 4998>,
			<6807 5439 5215 5055 5037 4998>,
			<6904 5425 5215 5056 5038 4998>,
			<6983 5462 5215 5058 5040 5000>,
			<7050 5518 5215 5061 5043 5001>,
			<7106 5576 5206 5065 5047 5004>,
			<7153 5644 5191 5069 5051 5007>,
			<7195 5697 5189 5070 5055 5011>,
			<7231 5738 5203 5071 5060 5015>,
			<7265 5775 5222 5071 5063 5017>,
			<7297 5815 5240 5072 5058 5012>,
			<7327 5856 5259 5073 5049 5003>,
			<7359 5895 5275 5073 5044 5000>,
			<7392 5932 5290 5071 5041 4999>,
			<7424 5971 5304 5071 5040 4998>,
			<7453 6017 5318 5072 5042 5000>,
			<7480 6067 5331 5074 5045 5002>,
			<7516 6119 5344 5075 5046 5002>,
			<7564 6176 5359 5076 5046 5001>,
			<7625 6240 5376 5081 5045 5001>,
			<7700 6313 5393 5083 5043 5002>,
			<7764 6379 5390 5070 5043 5001>,
			<7605 6324 5356 5077 5049 5005>,
			<7721 6377 5378 5081 5052 5007>,
			<7829 6483 5400 5087 5056 5013>,
			<7963 6569 5440 5097 5059 5018>,
			<8066 6664 5463 5092 5053 5010>,
			<8200 6764 5474 5092 5051 5006>,
			<8700 6931 5514 5107 5056 5012>,
			<9284 7223 5591 5127 5067 5023>,
			<10124 7694 5701 5162 5089 5043>,
			<10124 7694 5701 5162 5089 5043>,
			<10124 7694 5701 5162 5089 5043>;
	};

};
